# K32W041AM register map
Vendor: nxp.com; File version: 1.0
CPU: CM4 r0p1, little endian, MPU, no FPU, VTOR, 3 interrupt priority bits
Registers are 32-bit, read-write, reset 0x0 unless marked. A register's access mark holds for its fields unless they carry their own. Offsets are from the block's base; [hi:lo] are bit positions; {n}, {i} and the like mark numbered series.

## PWM — This is the description of component pwm. It is a Pulse Width Modulation Controller with an APB bus interface. More details will follow.
Base 0x4000C000
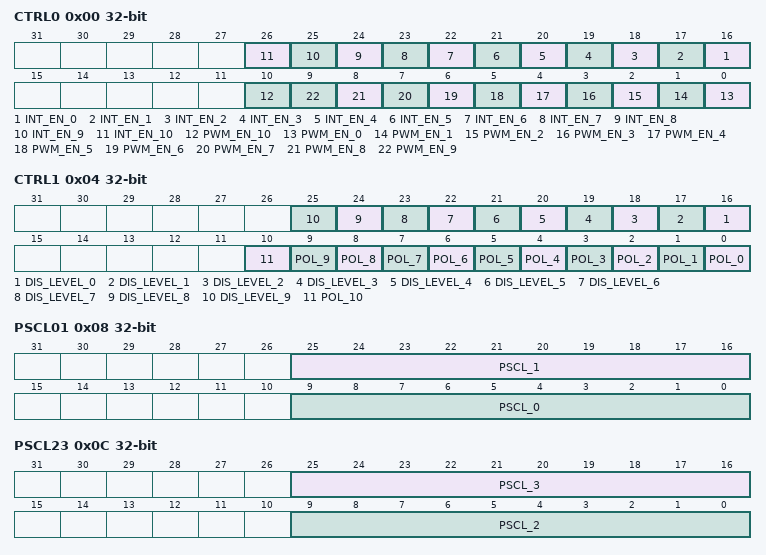
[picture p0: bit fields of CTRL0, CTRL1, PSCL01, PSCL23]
0x00 CTRL0 — PWM 1st Control Register (Channel 0 to Channel 10) for channel enables and interrupt enables. Note if all interrupts are enabled with short period timings it will not be possible to manage all the interrupts.
  [n+16] INT_EN_{n} (n=0..10) — PWM channel {n} interrupt enable. 0 = Disable / 1 = Enable.
  [10] PWM_EN_10 — PWM channel 10 enable. 0 = Disable / 1 = Enable. Note, this enables the common PWM mode where PWM10 will be routed to all PWM channels.
  [n] PWM_EN_{n} (n=0..9) — PWM channel {n} enable. 0 = Disable / 1 = Enable.
0x04 CTRL1 — PWM 2nd Control Register (Channel 0 to Channel 10) for channel polarity and output state for a disabled channel.
  [n+16] DIS_LEVEL_{n} (n=0..9) — PWM channel {n} output level when PWM channel 0 is disable. 0 = Low Level / 1 = High Level.
  [n] POL_{n} (n=0..10) — PWM channel {n} waveform Polarity control. 0: Set high on compare match, set low at the end of PWM period. 1: Set low on compare match, set high at the end of PWM period
0x08 PSCL01 — PWM Channels 0 & 1 prescalers
  [25:16] PSCL_1 — PWM channel 1 prescaler. The output frequency equals to clk/(PSCL_1 + 1)
  [9:0] PSCL_0 — PWM channel 0 prescaler. The output frequency equals to clk/(PSCL_0 + 1)
0x0C PSCL23 — PWM Channels 2 & 3 prescalers
  [25:16] PSCL_3 — PWM channel 3 prescaler. The output frequency equals to clk/(PSCL_3 + 1)
  [9:0] PSCL_2 — PWM channel 2 prescaler. The output frequency equals to clk/(PSCL_2 + 1)
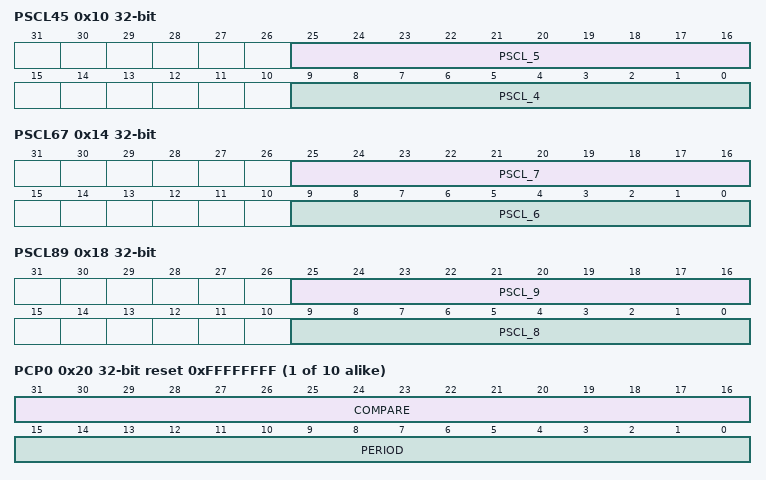
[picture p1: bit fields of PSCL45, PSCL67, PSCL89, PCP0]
0x10 PSCL45 — PWM Channels 4 & 5 prescalers
  [25:16] PSCL_5 — PWM channel 5 prescaler. The output frequency equals to clk/(PSCL_5 + 1)
  [9:0] PSCL_4 — PWM channel 4 prescaler. The output frequency equals to clk/(PSCL_4 + 1)
0x14 PSCL67 — PWM Channels 6 & 7 prescalers
  [25:16] PSCL_7 — PWM channel 7 prescaler. The output frequency equals to clk/(PSCL_7 + 1)
  [9:0] PSCL_6 — PWM channel 6 prescaler. The output frequency equals to clk/(PSCL_6 + 1)
0x18 PSCL89 — PWM Channels 8 & 9 prescalers
  [25:16] PSCL_9 — PWM channel 9 prescaler. The output frequency equals to clk/(PSCL_9 + 1)
  [9:0] PSCL_8 — PWM channel 8 prescaler. The output frequency equals to clk/(PSCL_8 + 1)
0x1C PSCL1011 — PWM Channel 10 prescaler
  [9:0] PSCL_10 — PWM channel 10 prescaler. The output frequency equals to clk/(PSCL_10 + 1)
{0x20+4i} PCP{i} reset 0xFFFFFFFF (i=0..9) — PWM Channel {i} Period and Compare register. Counter will count down from period to zero. When Comapre value is reached PWM output will change on next counter decrement and be stable from 'Compare-1' to 0.
  [31:16] COMPARE — PWM channel {i} compare register. 'COMPARE' must not be 0x0.
  [15:0] PERIOD — PWM channel {i} period register. The actual period equals to [PERIOD + 1]. 'PERIOD' must not be 0x0.
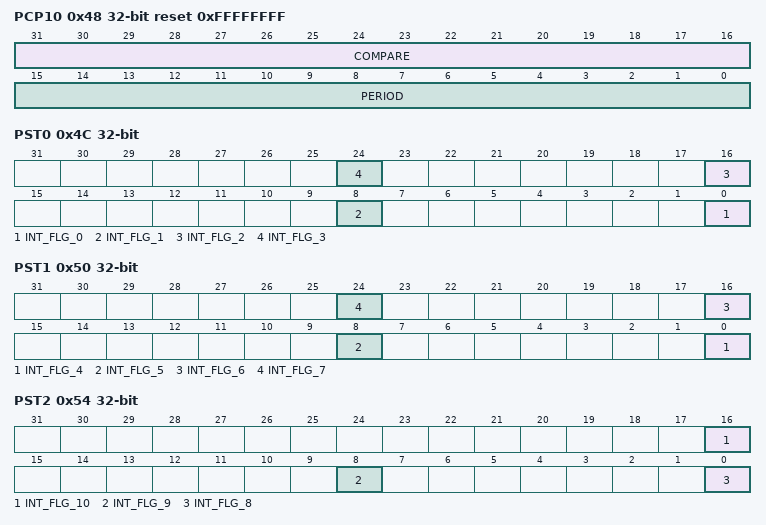
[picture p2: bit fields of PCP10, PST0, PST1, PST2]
0x48 PCP10 reset 0xFFFFFFFF — PWM Channel 10 Period and Compare register. Counter will count down from period to zero. When Comapre value is reached all PWM outputs will change on next counter decrement and be stable from 'Compare-1' to 0.
  [31:16] COMPARE — PWM channel 10 compare register. 'COMPARE' must not be 0x0.
  [15:0] PERIOD — PWM channel 10 period register. The actual period equals to [PERIOD + 1]. 'PERIOD' must not be 0x0.
0x4C PST0 — PWM 1st Status Register (Channel 0 to Channel 3)
  [8n] INT_FLG_{n} (n=0..3) — PWM channel {n} interrupt flag. 0: No interrupt pending. 1: Interrupt pending. Write 1 to clear the interrupt.
0x50 PST1 — PWM 2nd Status Register (Channel 4 to Channel 7)
  [8n-32] INT_FLG_{n} (n=4..7) — PWM channel {n} interrupt flag. 0: No interrupt pending. 1: Interrupt pending. Write 1 to clear the interrupt.
0x54 PST2 — PWM 3rd Status Register (Channel 8 to Channel 10)
  [16] INT_FLG_10 — PWM channel 10 interrupt flag. 0: No interrupt pending. 1: Interrupt pending. Write 1 to clear the interrupt.
  [8] INT_FLG_9 — PWM channel 9 interrupt flag. 0: No interrupt pending. 1: Interrupt pending. Write 1 to clear the interrupt.
  [0] INT_FLG_8 — PWM channel 8 interrupt flag. 0: No interrupt pending. 1: Interrupt pending. Write 1 to clear the interrupt.
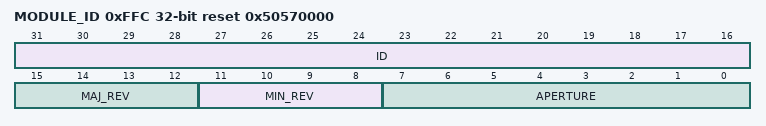
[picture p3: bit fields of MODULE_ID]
0xFFC MODULE_ID ro reset 0x50570000 — PWM Module Identifier ('PW' in ASCII)
  [31:16] ID — Identifier. This is the unique identifier of the module
  [15:12] MAJ_REV — Major revision i.e. implies software modifications
  [11:8] MIN_REV — Minor revision i.e. with no software consequences
  [7:0] APERTURE — Aperture i.e. number minus 1 of consecutive packets 4 Kbytes reserved for this IP
